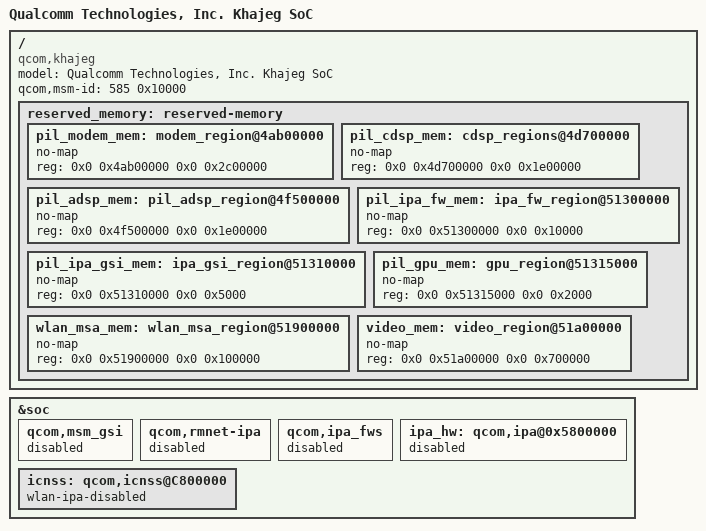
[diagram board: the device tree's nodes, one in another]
/dts-v1/;

#include "khaje.dtsi"

/ {
	model = "Qualcomm Technologies, Inc. Khajeg SoC";
	compatible = "qcom,khajeg";
	qcom,msm-id = <585 0x10000>;

reserved_memory: reserved-memory {
	/delete-node/ modem_region@4ab00000;
	/delete-node/ wlan_msa_region@51900000;
	/delete-node/ cdsp_regions@51a00000;
	/delete-node/ pil_adsp_region@53800000;
	/delete-node/ ipa_fw_region@55600000;
	/delete-node/ ipa_gsi_region@55610000;
	/delete-node/ gpu_region@55615000;
	/delete-node/ video_region@55617000;

	pil_modem_mem: modem_region@4ab00000 {
		no-map;
		reg = <0x0 0x4ab00000 0x0 0x2c00000>;
	};

	pil_cdsp_mem: cdsp_regions@4d700000 {
		no-map;
		reg = <0x0 0x4d700000 0x0 0x1e00000>;
	};

	pil_adsp_mem: pil_adsp_region@4f500000 {
		no-map;
		reg = <0x0 0x4f500000 0x0 0x1e00000>;
	};

	pil_ipa_fw_mem: ipa_fw_region@51300000 {
		no-map;
		reg = <0x0 0x51300000 0x0 0x10000>;
	};

	pil_ipa_gsi_mem: ipa_gsi_region@51310000 {
		no-map;
		reg = <0x0 0x51310000 0x0 0x5000>;
	};

	pil_gpu_mem: gpu_region@51315000 {
		no-map;
		reg = <0x0 0x51315000 0x0 0x2000>;
	};

	wlan_msa_mem: wlan_msa_region@51900000 {
		no-map;
		reg = <0x0 0x51900000 0x0 0x100000>;
	};

	video_mem: video_region@51a00000 {
		no-map;
		reg = <0x0 0x51a00000 0x0 0x700000>;
	};
};
};

&soc {
	qcom,msm_gsi {
		status = "disabled";
	};

	qcom,rmnet-ipa {
		status = "disabled";
	};

	qcom,ipa_fws {
		status = "disabled";
	};

	ipa_hw: qcom,ipa@0x5800000 {
		status = "disabled";
	};

	icnss: qcom,icnss@C800000 {
		wlan-ipa-disabled;
	};
};
